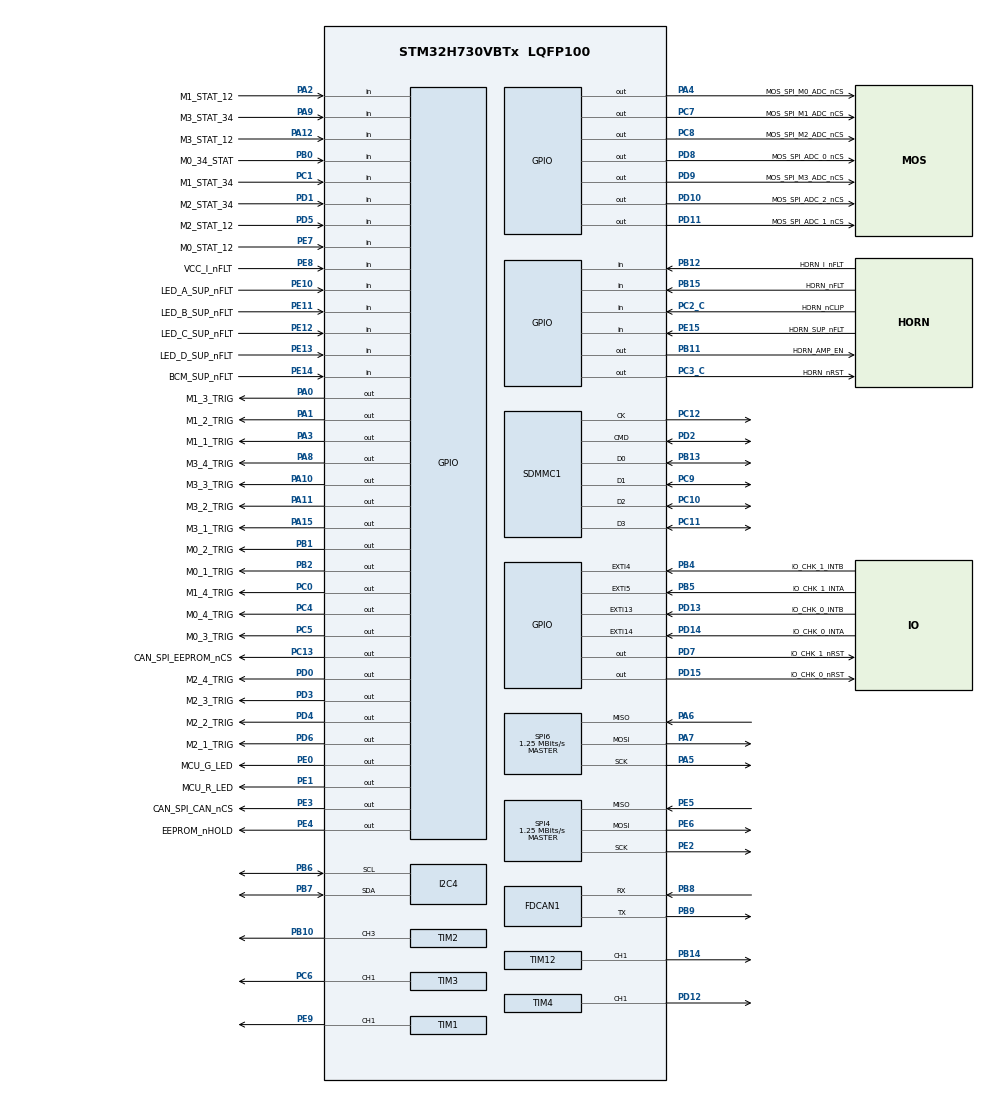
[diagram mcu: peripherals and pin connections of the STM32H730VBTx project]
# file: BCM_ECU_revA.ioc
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CORTEX_M7.default_mode_Activation=1
FDCAN1.CalculateBaudRateNominal=52083
FDCAN1.CalculateTimeBitNominal=19200
FDCAN1.CalculateTimeQuantumNominal=6400.0
I2C4.Timing=0x00000E14
Mcu.Family=STM32H7
Mcu.Name=STM32H730VBTx
Mcu.Package=LQFP100
NVIC.PriorityGroup=NVIC_PRIORITYGROUP_4
NVIC.TIM6_DAC_IRQn=true\:0\:0\:false\:false\:true\:true\:true\:true
PA0.GPIO_Label=M1_3_TRIG
PA0.Signal=GPIO_Output
PA1.GPIO_Label=M1_2_TRIG
PA1.Signal=GPIO_Output
PA10.GPIO_Label=M3_3_TRIG
PA10.Signal=GPIO_Output
PA11.GPIO_Label=M3_2_TRIG
PA11.Signal=GPIO_Output
PA12.GPIO_Label=M3_STAT_12
PA12.Signal=GPIO_Input
PA13(JTMS/SWDIO).Mode=Trace_Asynchronous_SW
PA13(JTMS/SWDIO).Signal=DEBUG_JTMS-SWDIO
PA14(JTCK/SWCLK).Mode=Trace_Asynchronous_SW
PA14(JTCK/SWCLK).Signal=DEBUG_JTCK-SWCLK
PA15(JTDI).GPIO_Label=M3_1_TRIG
PA15(JTDI).Signal=GPIO_Output
PA2.GPIO_Label=M1_STAT_12
PA2.Signal=GPIO_Input
PA3.GPIO_Label=M1_1_TRIG
PA3.Signal=GPIO_Output
PA4.GPIO_Label=MOS_SPI_M0_ADC_nCS
PA4.Signal=GPIO_Output
PA5.Mode=Full_Duplex_Master
PA5.Signal=SPI6_SCK
PA6.Mode=Full_Duplex_Master
PA6.Signal=SPI6_MISO
PA7.Mode=Full_Duplex_Master
PA7.Signal=SPI6_MOSI
PA8.GPIO_Label=M3_4_TRIG
PA8.Signal=GPIO_Output
PA9.GPIO_Label=M3_STAT_34
PA9.Signal=GPIO_Input
PB0.GPIO_Label=M0_34_STAT
PB0.Signal=GPIO_Input
PB1.GPIO_Label=M0_2_TRIG
PB1.Signal=GPIO_Output
PB10.Signal=S_TIM2_CH3
PB11.GPIO_Label=HORN_AMP_EN
PB11.Signal=GPIO_Output
PB12.GPIO_Label=HORN_I_nFLT
PB12.GPIO_PuPd=GPIO_PULLUP
PB12.Signal=GPIO_Input
PB13.Mode=SD_4_bits_Wide_bus
PB13.Signal=SDMMC1_D0
PB14.Signal=S_TIM12_CH1
PB15.GPIO_Label=HORN_nFLT
PB15.Signal=GPIO_Input
PB2.GPIO_Label=M0_1_TRIG
PB2.Signal=GPIO_Output
PB3(JTDO/TRACESWO).Mode=Trace_Asynchronous_SW
PB3(JTDO/TRACESWO).Signal=DEBUG_JTDO-SWO
PB4(NJTRST).GPIO_Label=IO_CHK_1_INTB
PB4(NJTRST).Signal=GPXTI4
PB5.GPIO_Label=IO_CHK_1_INTA
PB5.Signal=GPXTI5
PB6.Mode=I2C
PB6.Signal=I2C4_SCL
PB7.Mode=I2C
PB7.Signal=I2C4_SDA
PB8.Mode=FDCAN_Activate
PB8.Signal=FDCAN1_RX
PB9.Mode=FDCAN_Activate
PB9.Signal=FDCAN1_TX
PC0.GPIO_Label=M1_4_TRIG
PC0.Signal=GPIO_Output
PC1.GPIO_Label=M1_STAT_34
PC1.Signal=GPIO_Input
PC10.Mode=SD_4_bits_Wide_bus
PC10.Signal=SDMMC1_D2
PC11.Mode=SD_4_bits_Wide_bus
PC11.Signal=SDMMC1_D3
PC12.Mode=SD_4_bits_Wide_bus
PC12.Signal=SDMMC1_CK
PC13.GPIO_Label=CAN_SPI_EEPROM_nCS
PC13.Signal=GPIO_Output
PC14-OSC32_IN.Mode=LSE-External-Oscillator
PC14-OSC32_IN.Signal=RCC_OSC32_IN
PC15-OSC32_OUT.Mode=LSE-External-Oscillator
PC15-OSC32_OUT.Signal=RCC_OSC32_OUT
PC2_C.GPIO_Label=HORN_nCLIP
PC2_C.Signal=GPIO_Input
PC3_C.GPIO_Label=HORN_nRST
PC3_C.Signal=GPIO_Output
PC4.GPIO_Label=M0_4_TRIG
PC4.Signal=GPIO_Output
PC5.GPIO_Label=M0_3_TRIG
PC5.Signal=GPIO_Output
PC6.Signal=S_TIM3_CH1
PC7.GPIO_Label=MOS_SPI_M1_ADC_nCS
PC7.Signal=GPIO_Output
PC8.GPIO_Label=MOS_SPI_M2_ADC_nCS
PC8.Signal=GPIO_Output
PC9.Mode=SD_4_bits_Wide_bus
PC9.Signal=SDMMC1_D1
PD0.GPIO_Label=M2_4_TRIG
PD0.Signal=GPIO_Output
PD1.GPIO_Label=M2_STAT_34
PD1.Signal=GPIO_Input
PD10.GPIO_Label=MOS_SPI_ADC_2_nCS
PD10.Signal=GPIO_Output
PD11.GPIO_Label=MOS_SPI_ADC_1_nCS
PD11.Signal=GPIO_Output
PD12.Signal=S_TIM4_CH1
PD13.GPIO_Label=IO_CHK_0_INTB
PD13.Signal=GPXTI13
PD14.GPIO_Label=IO_CHK_0_INTA
PD14.Signal=GPXTI14
PD15.GPIO_Label=IO_CHK_0_nRST
PD15.Signal=GPIO_Output
PD2.Mode=SD_4_bits_Wide_bus
PD2.Signal=SDMMC1_CMD
PD3.GPIO_Label=M2_3_TRIG
PD3.Signal=GPIO_Output
PD4.GPIO_Label=M2_2_TRIG
PD4.Signal=GPIO_Output
PD5.GPIO_Label=M2_STAT_12
PD5.Signal=GPIO_Input
PD6.GPIO_Label=M2_1_TRIG
PD6.Signal=GPIO_Output
PD7.GPIO_Label=IO_CHK_1_nRST
PD7.Signal=GPIO_Output
PD8.GPIO_Label=MOS_SPI_ADC_0_nCS
PD8.Signal=GPIO_Output
PD9.GPIO_Label=MOS_SPI_M3_ADC_nCS
PD9.Signal=GPIO_Output
PE0.GPIO_Label=MCU_G_LED
PE0.Signal=GPIO_Output
PE1.GPIO_Label=MCU_R_LED
PE1.Signal=GPIO_Output
PE10.GPIO_Label=LED_A_SUP_nFLT
PE10.Signal=GPIO_Input
PE11.GPIO_Label=LED_B_SUP_nFLT
PE11.Signal=GPIO_Input
PE12.GPIO_Label=LED_C_SUP_nFLT
PE12.Signal=GPIO_Input
PE13.GPIO_Label=LED_D_SUP_nFLT
PE13.Signal=GPIO_Input
PE14.GPIO_Label=BCM_SUP_nFLT
PE14.Signal=GPIO_Input
PE15.GPIO_Label=HORN_SUP_nFLT
PE15.Signal=GPIO_Input
PE2.Mode=Full_Duplex_Master
PE2.Signal=SPI4_SCK
PE3.GPIO_Label=CAN_SPI_CAN_nCS
PE3.Signal=GPIO_Output
PE4.GPIO_Label=EEPROM_nHOLD
PE4.Signal=GPIO_Output
PE5.Mode=Full_Duplex_Master
PE5.Signal=SPI4_MISO
PE6.Mode=Full_Duplex_Master
PE6.Signal=SPI4_MOSI
PE7.GPIO_Label=M0_STAT_12
PE7.Signal=GPIO_Input
PE8.GPIO_Label=VCC_I_nFLT
PE8.Signal=GPIO_Input
PE9.Signal=S_TIM1_CH1
PH0-OSC_IN.Mode=HSE-External-Oscillator
PH0-OSC_IN.Signal=RCC_OSC_IN
PH1-OSC_OUT.Mode=HSE-External-Oscillator
PH1-OSC_OUT.Signal=RCC_OSC_OUT
ProjectManager.HeapSize=0x200
ProjectManager.StackSize=0x400
ProjectManager.TargetToolchain=STM32CubeIDE
RCC.ADCFreq_Value=120000000
RCC.APB1Freq_Value=15000000
RCC.APB2Freq_Value=15000000
RCC.APB3Freq_Value=15000000
RCC.APB4Freq_Value=15000000
RCC.CortexFreq_Value=120000000
RCC.DIVM1=5
RCC.DIVM2=5
RCC.DIVN1=48
RCC.DIVN2=48
RCC.DIVQ1=3
RCC.DIVQ2=96
RCC.FDCANCLockSelection=RCC_FDCANCLKSOURCE_PLL2
RCC.HCLKFreq_Value=15000000
RCC.HPRE=RCC_HCLK_DIV8
RCC.I2C4CLockSelection=RCC_I2C4CLKSOURCE_CSI
RCC.PLLSourceVirtual=RCC_PLLSOURCE_HSE
RCC.SPI6CLockSelection=RCC_SPI6CLKSOURCE_PLL2
RCC.SYSCLKFreq_VALUE=120000000
RCC.SYSCLKSource=RCC_SYSCLKSOURCE_PLLCLK
RCC.Spi45ClockSelection=RCC_SPI45CLKSOURCE_PLL2
RCC.USBFreq_Value=80000000
SH.S_TIM12_CH1.0=TIM12_CH1,PWM Generation1 CH1
SH.S_TIM1_CH1.0=TIM1_CH1,PWM Generation1 CH1
SH.S_TIM2_CH3.0=TIM2_CH3,PWM Generation3 CH3
SH.S_TIM3_CH1.0=TIM3_CH1,PWM Generation1 CH1
SH.S_TIM4_CH1.0=TIM4_CH1,PWM Generation1 CH1
SPI4.CalculateBaudRate=1.25 MBits/s
SPI4.Direction=SPI_DIRECTION_2LINES
SPI4.Mode=SPI_MODE_MASTER
SPI4.VirtualType=VM_MASTER
SPI6.BaudRatePrescaler=SPI_BAUDRATEPRESCALER_2
SPI6.CalculateBaudRate=1.25 MBits/s
SPI6.Direction=SPI_DIRECTION_2LINES
SPI6.Mode=SPI_MODE_MASTER
SPI6.VirtualType=VM_MASTER
TIM1.Channel-PWM\ Generation1\ CH1=TIM_CHANNEL_1
TIM12.Channel-PWM\ Generation1\ CH1=TIM_CHANNEL_1
TIM2.Channel-PWM\ Generation3\ CH3=TIM_CHANNEL_3
TIM3.Channel-PWM\ Generation1\ CH1=TIM_CHANNEL_1
TIM4.Channel-PWM\ Generation1\ CH1=TIM_CHANNEL_1
TIM6.AutoReloadPreload=TIM_AUTORELOAD_PRELOAD_ENABLE
TIM6.Period=99
TIM6.Prescaler=1499
VP_MEMORYMAP_VS_MEMORYMAP.Mode=CurAppReg
VP_TIM6_VS_ClockSourceINT.Mode=Enable_Timer
board=custom

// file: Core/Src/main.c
/* USER CODE BEGIN Header */
/**
  ******************************************************************************
  * @file           : main.c
  * @brief          : Main program body
  ******************************************************************************
  * @attention
  *
  * Copyright (c) 2025 STMicroelectronics.
  * All rights reserved.
  *
  * This software is licensed under terms that can be found in the LICENSE file
  * in the root directory of this software component.
  * If no LICENSE file comes with this software, it is provided AS-IS.
  *
  ******************************************************************************
  */
/* USER CODE END Header */
#include "main.h"

/* USER CODE BEGIN Includes */

#include "ADC108S022.h"
#include "MCP23017.h"
#include "tcan1146.h"
#include "ws2812b.h"

#include "state_manager.h"
#include "light_manager.h"

/* USER CODE END Includes */

FDCAN_HandleTypeDef hfdcan1;

I2C_HandleTypeDef hi2c4;

SD_HandleTypeDef hsd1;

SPI_HandleTypeDef hspi4;
SPI_HandleTypeDef hspi6;

TIM_HandleTypeDef htim1;
TIM_HandleTypeDef htim2;
TIM_HandleTypeDef htim3;
TIM_HandleTypeDef htim4;
TIM_HandleTypeDef htim6;
TIM_HandleTypeDef htim12;

/* USER CODE BEGIN PV */

ADC108S022 ADC_MOS_0 = {
    .hspi = &hspi6,
    .cs_port = GPIOA,        // CS on PA4
    .cs_pin = GPIO_PIN_4
};

ADC108S022 ADC_MOS_1 = {
    .hspi = &hspi6,
    .cs_port = GPIOC,        // CS on PC7
    .cs_pin = GPIO_PIN_7
};

ADC108S022 ADC_MOS_2 = {
    .hspi = &hspi6,
    .cs_port = GPIOC,        // CS on PC8
    .cs_pin = GPIO_PIN_8
};

ADC108S022 ADC_MOS_3 = {
    .hspi = &hspi6,
    .cs_port = GPIOD,        // CS on PD9
    .cs_pin = GPIO_PIN_9
};

ADC108S022 ADC_GEN_0 = {
    .hspi = &hspi6,
    .cs_port = GPIOD,        // CS on PD8
    .cs_pin = GPIO_PIN_8
};

ADC108S022 ADC_GEN_1 = {
    .hspi = &hspi6,
    .cs_port = GPIOD,        // CS on PD11
    .cs_pin = GPIO_PIN_11
};

ADC108S022 ADC_GEN_2 = {
    .hspi = &hspi6,
    .cs_port = GPIOD,        // CS on PD10
    .cs_pin = GPIO_PIN_10
};

MCP23017 MCP23017_0 = {			//TODO: update and make interrupt code
    .i2c = &hi2c4,             // I2C1 peripheral
    .i2c_addr = 0x20,          // A2/A1/A0 = GND
    .rst_port = GPIOD,         // RST on PD15
    .rst_pin = GPIO_PIN_15,
    .inta_port = GPIOD,        // INTA on PD14
    .inta_pin = GPIO_PIN_14,
    .intb_port = GPIOD,        // INTB on PD13
    .intb_pin = GPIO_PIN_13
};

MCP23017 MCP23017_1 = { 		//TODO: update
    .i2c = &hi2c4,             // I2C1 peripheral
    .i2c_addr = 0x20,          // A2/A1/A0 = GND
    .rst_port = GPIOD,         // RST on PD7
    .rst_pin = GPIO_PIN_7,
    .inta_port = GPIOB,        // INTA on PB5
    .inta_pin = GPIO_PIN_5,
    .intb_port = GPIOB,        // INTB on PB4
    .intb_pin = GPIO_PIN_4
};

TCAN1146 tcan = {
    .hspi = &hspi4,          // SPI1
    .cs_port = GPIOE,        // CS on PE3
    .cs_pin = GPIO_PIN_3
};

WS2812B_Strip strip1 = {
    .htim = &htim1,               // TIM1
    .channel = TIM_CHANNEL_1,     // PWM Channel 1
    .hdma = &hdma_tim1_ch1,       // DMA for TIM1_CH1
    .num_leds = 30,               // 30 LEDs in this strip
    .pwm_buffer = {0}             // Zero-init buffer
};

WS2812B_Strip strip2 = {
    .htim = &htim2,               // TIM2
    .channel = TIM_CHANNEL_2,     // PWM Channel 2
    .hdma = &hdma_tim2_ch2,       // DMA for TIM2_CH2
    .num_leds = 60,               // 60 LEDs in this strip
    .pwm_buffer = {0}             // Zero-init buffer
};

uint32_t wake_id = 0x12345678;	//TODO: UPDATE THESE VARS
uint8_t wake_payload[] = {0xAA, 0xBB};
uint8_t wake_payload_length = 2;

/* USER CODE END PV */

void SystemClock_Config(void);
void PeriphCommonClock_Config(void);
static void MPU_Config(void);
static void MX_GPIO_Init(void);
static void MX_FDCAN1_Init(void);
static void MX_I2C4_Init(void);
static void MX_SDMMC1_SD_Init(void);
static void MX_SPI4_Init(void);
static void MX_SPI6_Init(void);
static void MX_TIM1_Init(void);
static void MX_TIM2_Init(void);
static void MX_TIM3_Init(void);
static void MX_TIM4_Init(void);
static void MX_TIM12_Init(void);
static void MX_TIM6_Init(void);

int main(void)
{

  /* MPU Configuration--------------------------------------------------------*/
  MPU_Config();

  /* MCU Configuration--------------------------------------------------------*/

  /* Reset of all peripherals, Initializes the Flash interface and the Systick. */
  HAL_Init();

  /* Configure the system clock */
  SystemClock_Config();

  /* Configure the peripherals common clocks */
  PeriphCommonClock_Config();

  /* Initialize all configured peripherals */
  MX_GPIO_Init();
  MX_FDCAN1_Init();
  MX_I2C4_Init();
  MX_SDMMC1_SD_Init();
  MX_SPI4_Init();
  MX_SPI6_Init();
  MX_TIM1_Init();
  MX_TIM2_Init();
  MX_TIM3_Init();
  MX_TIM4_Init();
  MX_TIM12_Init();
  MX_TIM6_Init();
  /* USER CODE BEGIN 2 */

  ADC108S022_Init(&ADC_MOS_0);
  ADC108S022_Init(&ADC_MOS_1);
  ADC108S022_Init(&ADC_MOS_2);
  ADC108S022_Init(&ADC_MOS_3);
  ADC108S022_Init(&ADC_GEN_0);
  ADC108S022_Init(&ADC_GEN_1);
  ADC108S022_Init(&ADC_GEN_2);

  MCP23017_Init(&MCP23017_0);
  MCP23017_Init(&MCP23017_1);

  TCAN1146_Init(&tcan, wake_id, wake_payload, wake_payload_length);

  // Initialize strips (assigns hardware, uses num_leds)
  WS2812B_Init(&strip1);
  WS2812B_Init(&strip2);

  //TIM6 is used for regular lighting update interrupts
  HAL_TIM_Base_Start_IT(&htim6);  // Start TIM6 interrupts

  /* USER CODE END 2 */

  /* Infinite loop */
  while (1)
  {

  }
}

// Callback for interrupts caused by timers
void HAL_TIM_PeriodElapsedCallback(TIM_HandleTypeDef *htim) {
    if (htim == &htim6) {
        //update lights
    }
}

void SystemClock_Config(void)
{
  RCC_OscInitTypeDef RCC_OscInitStruct = {0};
  RCC_ClkInitTypeDef RCC_ClkInitStruct = {0};

  /** Supply configuration update enable
  */
  HAL_PWREx_ConfigSupply(PWR_LDO_SUPPLY);

  /** Configure the main internal regulator output voltage
  */
  __HAL_PWR_VOLTAGESCALING_CONFIG(PWR_REGULATOR_VOLTAGE_SCALE3);

  while(!__HAL_PWR_GET_FLAG(PWR_FLAG_VOSRDY)) {}

  /** Initializes the RCC Oscillators according to the specified parameters
  * in the RCC_OscInitTypeDef structure.
  */
  RCC_OscInitStruct.OscillatorType = RCC_OSCILLATORTYPE_CSI|RCC_OSCILLATORTYPE_HSE;
  RCC_OscInitStruct.HSEState = RCC_HSE_ON;
  RCC_OscInitStruct.CSIState = RCC_CSI_ON;
  RCC_OscInitStruct.CSICalibrationValue = 16;
  RCC_OscInitStruct.PLL.PLLState = RCC_PLL_ON;
  RCC_OscInitStruct.PLL.PLLSource = RCC_PLLSOURCE_HSE;
  RCC_OscInitStruct.PLL.PLLM = 5;
  RCC_OscInitStruct.PLL.PLLN = 48;
  RCC_OscInitStruct.PLL.PLLP = 2;
  RCC_OscInitStruct.PLL.PLLQ = 3;
  RCC_OscInitStruct.PLL.PLLR = 2;
  RCC_OscInitStruct.PLL.PLLRGE = RCC_PLL1VCIRANGE_2;
  RCC_OscInitStruct.PLL.PLLVCOSEL = RCC_PLL1VCOWIDE;
  RCC_OscInitStruct.PLL.PLLFRACN = 0;
  if (HAL_RCC_OscConfig(&RCC_OscInitStruct) != HAL_OK)
  {
    Error_Handler();
  }

  /** Initializes the CPU, AHB and APB buses clocks
  */
  RCC_ClkInitStruct.ClockType = RCC_CLOCKTYPE_HCLK|RCC_CLOCKTYPE_SYSCLK
                              |RCC_CLOCKTYPE_PCLK1|RCC_CLOCKTYPE_PCLK2
                              |RCC_CLOCKTYPE_D3PCLK1|RCC_CLOCKTYPE_D1PCLK1;
  RCC_ClkInitStruct.SYSCLKSource = RCC_SYSCLKSOURCE_PLLCLK;
  RCC_ClkInitStruct.SYSCLKDivider = RCC_SYSCLK_DIV1;
  RCC_ClkInitStruct.AHBCLKDivider = RCC_HCLK_DIV8;
  RCC_ClkInitStruct.APB3CLKDivider = RCC_APB3_DIV1;
  RCC_ClkInitStruct.APB1CLKDivider = RCC_APB1_DIV1;
  RCC_ClkInitStruct.APB2CLKDivider = RCC_APB2_DIV1;
  RCC_ClkInitStruct.APB4CLKDivider = RCC_APB4_DIV1;

  if (HAL_RCC_ClockConfig(&RCC_ClkInitStruct, FLASH_LATENCY_0) != HAL_OK)
  {
    Error_Handler();
  }
}

void PeriphCommonClock_Config(void)
{
  RCC_PeriphCLKInitTypeDef PeriphClkInitStruct = {0};

  /** Initializes the peripherals clock
  */
  PeriphClkInitStruct.PeriphClockSelection = RCC_PERIPHCLK_SPI6|RCC_PERIPHCLK_SPI4
                              |RCC_PERIPHCLK_FDCAN;
  PeriphClkInitStruct.PLL2.PLL2M = 5;
  PeriphClkInitStruct.PLL2.PLL2N = 48;
  PeriphClkInitStruct.PLL2.PLL2P = 2;
  PeriphClkInitStruct.PLL2.PLL2Q = 96;
  PeriphClkInitStruct.PLL2.PLL2R = 2;
  PeriphClkInitStruct.PLL2.PLL2RGE = RCC_PLL2VCIRANGE_2;
  PeriphClkInitStruct.PLL2.PLL2VCOSEL = RCC_PLL2VCOWIDE;
  PeriphClkInitStruct.PLL2.PLL2FRACN = 0;
  PeriphClkInitStruct.Spi45ClockSelection = RCC_SPI45CLKSOURCE_PLL2;
  PeriphClkInitStruct.FdcanClockSelection = RCC_FDCANCLKSOURCE_PLL2;
  PeriphClkInitStruct.Spi6ClockSelection = RCC_SPI6CLKSOURCE_PLL2;
  if (HAL_RCCEx_PeriphCLKConfig(&PeriphClkInitStruct) != HAL_OK)
  {
    Error_Handler();
  }
}

static void MX_FDCAN1_Init(void)
{

  hfdcan1.Instance = FDCAN1;
  hfdcan1.Init.FrameFormat = FDCAN_FRAME_CLASSIC;
  hfdcan1.Init.Mode = FDCAN_MODE_NORMAL;
  hfdcan1.Init.AutoRetransmission = DISABLE;
  hfdcan1.Init.TransmitPause = DISABLE;
  hfdcan1.Init.ProtocolException = DISABLE;
  hfdcan1.Init.NominalPrescaler = 16;
  hfdcan1.Init.NominalSyncJumpWidth = 1;
  hfdcan1.Init.NominalTimeSeg1 = 1;
  hfdcan1.Init.NominalTimeSeg2 = 1;
  hfdcan1.Init.DataPrescaler = 1;
  hfdcan1.Init.DataSyncJumpWidth = 1;
  hfdcan1.Init.DataTimeSeg1 = 1;
  hfdcan1.Init.DataTimeSeg2 = 1;
  hfdcan1.Init.MessageRAMOffset = 0;
  hfdcan1.Init.StdFiltersNbr = 0;
  hfdcan1.Init.ExtFiltersNbr = 0;
  hfdcan1.Init.RxFifo0ElmtsNbr = 0;
  hfdcan1.Init.RxFifo0ElmtSize = FDCAN_DATA_BYTES_8;
  hfdcan1.Init.RxFifo1ElmtsNbr = 0;
  hfdcan1.Init.RxFifo1ElmtSize = FDCAN_DATA_BYTES_8;
  hfdcan1.Init.RxBuffersNbr = 0;
  hfdcan1.Init.RxBufferSize = FDCAN_DATA_BYTES_8;
  hfdcan1.Init.TxEventsNbr = 0;
  hfdcan1.Init.TxBuffersNbr = 0;
  hfdcan1.Init.TxFifoQueueElmtsNbr = 0;
  hfdcan1.Init.TxFifoQueueMode = FDCAN_TX_FIFO_OPERATION;
  hfdcan1.Init.TxElmtSize = FDCAN_DATA_BYTES_8;
  if (HAL_FDCAN_Init(&hfdcan1) != HAL_OK)
  {
    Error_Handler();
  }

}

static void MX_I2C4_Init(void)
{

  hi2c4.Instance = I2C4;
  hi2c4.Init.Timing = 0x00000E14;
  hi2c4.Init.OwnAddress1 = 0;
  hi2c4.Init.AddressingMode = I2C_ADDRESSINGMODE_7BIT;
  hi2c4.Init.DualAddressMode = I2C_DUALADDRESS_DISABLE;
  hi2c4.Init.OwnAddress2 = 0;
  hi2c4.Init.OwnAddress2Masks = I2C_OA2_NOMASK;
  hi2c4.Init.GeneralCallMode = I2C_GENERALCALL_DISABLE;
  hi2c4.Init.NoStretchMode = I2C_NOSTRETCH_DISABLE;
  if (HAL_I2C_Init(&hi2c4) != HAL_OK)
  {
    Error_Handler();
  }

  /** Configure Analogue filter
  */
  if (HAL_I2CEx_ConfigAnalogFilter(&hi2c4, I2C_ANALOGFILTER_ENABLE) != HAL_OK)
  {
    Error_Handler();
  }

  /** Configure Digital filter
  */
  if (HAL_I2CEx_ConfigDigitalFilter(&hi2c4, 0) != HAL_OK)
  {
    Error_Handler();
  }

}

static void MX_SDMMC1_SD_Init(void)
{

  hsd1.Instance = SDMMC1;
  hsd1.Init.ClockEdge = SDMMC_CLOCK_EDGE_RISING;
  hsd1.Init.ClockPowerSave = SDMMC_CLOCK_POWER_SAVE_DISABLE;
  hsd1.Init.BusWide = SDMMC_BUS_WIDE_4B;
  hsd1.Init.HardwareFlowControl = SDMMC_HARDWARE_FLOW_CONTROL_DISABLE;
  hsd1.Init.ClockDiv = 0;
  if (HAL_SD_Init(&hsd1) != HAL_OK)
  {
    Error_Handler();
  }

}

static void MX_SPI4_Init(void)
{

  /* SPI4 parameter configuration*/
  hspi4.Instance = SPI4;
  hspi4.Init.Mode = SPI_MODE_MASTER;
  hspi4.Init.Direction = SPI_DIRECTION_2LINES;
  hspi4.Init.DataSize = SPI_DATASIZE_4BIT;
  hspi4.Init.CLKPolarity = SPI_POLARITY_LOW;
  hspi4.Init.CLKPhase = SPI_PHASE_1EDGE;
  hspi4.Init.NSS = SPI_NSS_SOFT;
  hspi4.Init.BaudRatePrescaler = SPI_BAUDRATEPRESCALER_2;
  hspi4.Init.FirstBit = SPI_FIRSTBIT_MSB;
  hspi4.Init.TIMode = SPI_TIMODE_DISABLE;
  hspi4.Init.CRCCalculation = SPI_CRCCALCULATION_DISABLE;
  hspi4.Init.CRCPolynomial = 0x0;
  hspi4.Init.NSSPMode = SPI_NSS_PULSE_ENABLE;
  hspi4.Init.NSSPolarity = SPI_NSS_POLARITY_LOW;
  hspi4.Init.FifoThreshold = SPI_FIFO_THRESHOLD_01DATA;
  hspi4.Init.TxCRCInitializationPattern = SPI_CRC_INITIALIZATION_ALL_ZERO_PATTERN;
  hspi4.Init.RxCRCInitializationPattern = SPI_CRC_INITIALIZATION_ALL_ZERO_PATTERN;
  hspi4.Init.MasterSSIdleness = SPI_MASTER_SS_IDLENESS_00CYCLE;
  hspi4.Init.MasterInterDataIdleness = SPI_MASTER_INTERDATA_IDLENESS_00CYCLE;
  hspi4.Init.MasterReceiverAutoSusp = SPI_MASTER_RX_AUTOSUSP_DISABLE;
  hspi4.Init.MasterKeepIOState = SPI_MASTER_KEEP_IO_STATE_DISABLE;
  hspi4.Init.IOSwap = SPI_IO_SWAP_DISABLE;
  if (HAL_SPI_Init(&hspi4) != HAL_OK)
  {
    Error_Handler();
  }

}

static void MX_SPI6_Init(void)
{

  /* SPI6 parameter configuration*/
  hspi6.Instance = SPI6;
  hspi6.Init.Mode = SPI_MODE_MASTER;
  hspi6.Init.Direction = SPI_DIRECTION_2LINES;
  hspi6.Init.DataSize = SPI_DATASIZE_4BIT;
  hspi6.Init.CLKPolarity = SPI_POLARITY_LOW;
  hspi6.Init.CLKPhase = SPI_PHASE_1EDGE;
  hspi6.Init.NSS = SPI_NSS_SOFT;
  hspi6.Init.BaudRatePrescaler = SPI_BAUDRATEPRESCALER_2;
  hspi6.Init.FirstBit = SPI_FIRSTBIT_MSB;
  hspi6.Init.TIMode = SPI_TIMODE_DISABLE;
  hspi6.Init.CRCCalculation = SPI_CRCCALCULATION_DISABLE;
  hspi6.Init.CRCPolynomial = 0x0;
  hspi6.Init.NSSPMode = SPI_NSS_PULSE_ENABLE;
  hspi6.Init.NSSPolarity = SPI_NSS_POLARITY_LOW;
  hspi6.Init.FifoThreshold = SPI_FIFO_THRESHOLD_01DATA;
  hspi6.Init.TxCRCInitializationPattern = SPI_CRC_INITIALIZATION_ALL_ZERO_PATTERN;
  hspi6.Init.RxCRCInitializationPattern = SPI_CRC_INITIALIZATION_ALL_ZERO_PATTERN;
  hspi6.Init.MasterSSIdleness = SPI_MASTER_SS_IDLENESS_00CYCLE;
  hspi6.Init.MasterInterDataIdleness = SPI_MASTER_INTERDATA_IDLENESS_00CYCLE;
  hspi6.Init.MasterReceiverAutoSusp = SPI_MASTER_RX_AUTOSUSP_DISABLE;
  hspi6.Init.MasterKeepIOState = SPI_MASTER_KEEP_IO_STATE_DISABLE;
  hspi6.Init.IOSwap = SPI_IO_SWAP_DISABLE;
  if (HAL_SPI_Init(&hspi6) != HAL_OK)
  {
    Error_Handler();
  }

}

static void MX_TIM1_Init(void)
{

  TIM_MasterConfigTypeDef sMasterConfig = {0};
  TIM_OC_InitTypeDef sConfigOC = {0};
  TIM_BreakDeadTimeConfigTypeDef sBreakDeadTimeConfig = {0};

  htim1.Instance = TIM1;
  htim1.Init.Prescaler = 0;
  htim1.Init.CounterMode = TIM_COUNTERMODE_UP;
  htim1.Init.Period = 65535;
  htim1.Init.ClockDivision = TIM_CLOCKDIVISION_DIV1;
  htim1.Init.RepetitionCounter = 0;
  htim1.Init.AutoReloadPreload = TIM_AUTORELOAD_PRELOAD_DISABLE;
  if (HAL_TIM_PWM_Init(&htim1) != HAL_OK)
  {
    Error_Handler();
  }
  sMasterConfig.MasterOutputTrigger = TIM_TRGO_RESET;
  sMasterConfig.MasterOutputTrigger2 = TIM_TRGO2_RESET;
  sMasterConfig.MasterSlaveMode = TIM_MASTERSLAVEMODE_DISABLE;
  if (HAL_TIMEx_MasterConfigSynchronization(&htim1, &sMasterConfig) != HAL_OK)
  {
    Error_Handler();
  }
  sConfigOC.OCMode = TIM_OCMODE_PWM1;
  sConfigOC.Pulse = 0;
  sConfigOC.OCPolarity = TIM_OCPOLARITY_HIGH;
  sConfigOC.OCNPolarity = TIM_OCNPOLARITY_HIGH;
  sConfigOC.OCFastMode = TIM_OCFAST_DISABLE;
  sConfigOC.OCIdleState = TIM_OCIDLESTATE_RESET;
  sConfigOC.OCNIdleState = TIM_OCNIDLESTATE_RESET;
  if (HAL_TIM_PWM_ConfigChannel(&htim1, &sConfigOC, TIM_CHANNEL_1) != HAL_OK)
  {
    Error_Handler();
  }
  sBreakDeadTimeConfig.OffStateRunMode = TIM_OSSR_DISABLE;
  sBreakDeadTimeConfig.OffStateIDLEMode = TIM_OSSI_DISABLE;
  sBreakDeadTimeConfig.LockLevel = TIM_LOCKLEVEL_OFF;
  sBreakDeadTimeConfig.DeadTime = 0;
  sBreakDeadTimeConfig.BreakState = TIM_BREAK_DISABLE;
  sBreakDeadTimeConfig.BreakPolarity = TIM_BREAKPOLARITY_HIGH;
  sBreakDeadTimeConfig.BreakFilter = 0;
  sBreakDeadTimeConfig.Break2State = TIM_BREAK2_DISABLE;
  sBreakDeadTimeConfig.Break2Polarity = TIM_BREAK2POLARITY_HIGH;
  sBreakDeadTimeConfig.Break2Filter = 0;
  sBreakDeadTimeConfig.AutomaticOutput = TIM_AUTOMATICOUTPUT_DISABLE;
  if (HAL_TIMEx_ConfigBreakDeadTime(&htim1, &sBreakDeadTimeConfig) != HAL_OK)
  {
    Error_Handler();
  }
  HAL_TIM_MspPostInit(&htim1);

}

static void MX_TIM2_Init(void)
{

  TIM_MasterConfigTypeDef sMasterConfig = {0};
  TIM_OC_InitTypeDef sConfigOC = {0};

  htim2.Instance = TIM2;
  htim2.Init.Prescaler = 0;
  htim2.Init.CounterMode = TIM_COUNTERMODE_UP;
  htim2.Init.Period = 4294967295;
  htim2.Init.ClockDivision = TIM_CLOCKDIVISION_DIV1;
  htim2.Init.AutoReloadPreload = TIM_AUTORELOAD_PRELOAD_DISABLE;
  if (HAL_TIM_PWM_Init(&htim2) != HAL_OK)
  {
    Error_Handler();
  }
  sMasterConfig.MasterOutputTrigger = TIM_TRGO_RESET;
  sMasterConfig.MasterSlaveMode = TIM_MASTERSLAVEMODE_DISABLE;
  if (HAL_TIMEx_MasterConfigSynchronization(&htim2, &sMasterConfig) != HAL_OK)
  {
    Error_Handler();
  }
  sConfigOC.OCMode = TIM_OCMODE_PWM1;
  sConfigOC.Pulse = 0;
  sConfigOC.OCPolarity = TIM_OCPOLARITY_HIGH;
  sConfigOC.OCFastMode = TIM_OCFAST_DISABLE;
  if (HAL_TIM_PWM_ConfigChannel(&htim2, &sConfigOC, TIM_CHANNEL_3) != HAL_OK)
  {
    Error_Handler();
  }
  HAL_TIM_MspPostInit(&htim2);

}

static void MX_TIM3_Init(void)
{

  TIM_MasterConfigTypeDef sMasterConfig = {0};
  TIM_OC_InitTypeDef sConfigOC = {0};

  htim3.Instance = TIM3;
  htim3.Init.Prescaler = 0;
  htim3.Init.CounterMode = TIM_COUNTERMODE_UP;
  htim3.Init.Period = 65535;
  htim3.Init.ClockDivision = TIM_CLOCKDIVISION_DIV1;
  htim3.Init.AutoReloadPreload = TIM_AUTORELOAD_PRELOAD_DISABLE;
  if (HAL_TIM_PWM_Init(&htim3) != HAL_OK)
  {
    Error_Handler();
  }
  sMasterConfig.MasterOutputTrigger = TIM_TRGO_RESET;
  sMasterConfig.MasterSlaveMode = TIM_MASTERSLAVEMODE_DISABLE;
  if (HAL_TIMEx_MasterConfigSynchronization(&htim3, &sMasterConfig) != HAL_OK)
  {
    Error_Handler();
  }
  sConfigOC.OCMode = TIM_OCMODE_PWM1;
  sConfigOC.Pulse = 0;
  sConfigOC.OCPolarity = TIM_OCPOLARITY_HIGH;
  sConfigOC.OCFastMode = TIM_OCFAST_DISABLE;
  if (HAL_TIM_PWM_ConfigChannel(&htim3, &sConfigOC, TIM_CHANNEL_1) != HAL_OK)
  {
    Error_Handler();
  }
  HAL_TIM_MspPostInit(&htim3);

}

static void MX_TIM4_Init(void)
{

  TIM_MasterConfigTypeDef sMasterConfig = {0};
  TIM_OC_InitTypeDef sConfigOC = {0};

  htim4.Instance = TIM4;
  htim4.Init.Prescaler = 0;
  htim4.Init.CounterMode = TIM_COUNTERMODE_UP;
  htim4.Init.Period = 65535;
  htim4.Init.ClockDivision = TIM_CLOCKDIVISION_DIV1;
  htim4.Init.AutoReloadPreload = TIM_AUTORELOAD_PRELOAD_DISABLE;
  if (HAL_TIM_PWM_Init(&htim4) != HAL_OK)
  {
    Error_Handler();
  }
  sMasterConfig.MasterOutputTrigger = TIM_TRGO_RESET;
  sMasterConfig.MasterSlaveMode = TIM_MASTERSLAVEMODE_DISABLE;
  if (HAL_TIMEx_MasterConfigSynchronization(&htim4, &sMasterConfig) != HAL_OK)
  {
    Error_Handler();
  }
  sConfigOC.OCMode = TIM_OCMODE_PWM1;
  sConfigOC.Pulse = 0;
  sConfigOC.OCPolarity = TIM_OCPOLARITY_HIGH;
  sConfigOC.OCFastMode = TIM_OCFAST_DISABLE;
  if (HAL_TIM_PWM_ConfigChannel(&htim4, &sConfigOC, TIM_CHANNEL_1) != HAL_OK)
  {
    Error_Handler();
  }
  HAL_TIM_MspPostInit(&htim4);

}

static void MX_TIM6_Init(void)
{

  TIM_MasterConfigTypeDef sMasterConfig = {0};

  htim6.Instance = TIM6;
  htim6.Init.Prescaler = 1499;
  htim6.Init.CounterMode = TIM_COUNTERMODE_UP;
  htim6.Init.Period = 99;
  htim6.Init.AutoReloadPreload = TIM_AUTORELOAD_PRELOAD_ENABLE;
  if (HAL_TIM_Base_Init(&htim6) != HAL_OK)
  {
    Error_Handler();
  }
  sMasterConfig.MasterOutputTrigger = TIM_TRGO_RESET;
  sMasterConfig.MasterSlaveMode = TIM_MASTERSLAVEMODE_DISABLE;
  if (HAL_TIMEx_MasterConfigSynchronization(&htim6, &sMasterConfig) != HAL_OK)
  {
    Error_Handler();
  }

}

static void MX_TIM12_Init(void)
{

  TIM_MasterConfigTypeDef sMasterConfig = {0};
  TIM_OC_InitTypeDef sConfigOC = {0};

  htim12.Instance = TIM12;
  htim12.Init.Prescaler = 0;
  htim12.Init.CounterMode = TIM_COUNTERMODE_UP;
  htim12.Init.Period = 65535;
  htim12.Init.ClockDivision = TIM_CLOCKDIVISION_DIV1;
  htim12.Init.AutoReloadPreload = TIM_AUTORELOAD_PRELOAD_DISABLE;
  if (HAL_TIM_PWM_Init(&htim12) != HAL_OK)
  {
    Error_Handler();
  }
  sMasterConfig.MasterOutputTrigger = TIM_TRGO_RESET;
  sMasterConfig.MasterSlaveMode = TIM_MASTERSLAVEMODE_DISABLE;
  if (HAL_TIMEx_MasterConfigSynchronization(&htim12, &sMasterConfig) != HAL_OK)
  {
    Error_Handler();
  }
  sConfigOC.OCMode = TIM_OCMODE_PWM1;
  sConfigOC.Pulse = 0;
  sConfigOC.OCPolarity = TIM_OCPOLARITY_HIGH;
  sConfigOC.OCFastMode = TIM_OCFAST_DISABLE;
  if (HAL_TIM_PWM_ConfigChannel(&htim12, &sConfigOC, TIM_CHANNEL_1) != HAL_OK)
  {
    Error_Handler();
  }
  HAL_TIM_MspPostInit(&htim12);

}

static void MX_GPIO_Init(void)
{
  GPIO_InitTypeDef GPIO_InitStruct = {0};

  /* GPIO Ports Clock Enable */
  __HAL_RCC_GPIOE_CLK_ENABLE();
  __HAL_RCC_GPIOC_CLK_ENABLE();
  __HAL_RCC_GPIOH_CLK_ENABLE();
  __HAL_RCC_GPIOA_CLK_ENABLE();
  __HAL_RCC_GPIOB_CLK_ENABLE();
  __HAL_RCC_GPIOD_CLK_ENABLE();

  /*Configure GPIO pin Output Level */
  HAL_GPIO_WritePin(GPIOE, CAN_SPI_CAN_nCS_Pin|EEPROM_nHOLD_Pin|MCU_G_LED_Pin|MCU_R_LED_Pin, GPIO_PIN_RESET);

  /*Configure GPIO pin Output Level */
  HAL_GPIO_WritePin(GPIOC, CAN_SPI_EEPROM_nCS_Pin|M1_4_TRIG_Pin|HORN_nRST_Pin|M0_4_TRIG_Pin
                          |M0_3_TRIG_Pin|MOS_SPI_M1_ADC_nCS_Pin|MOS_SPI_M2_ADC_nCS_Pin, GPIO_PIN_RESET);

  /*Configure GPIO pin Output Level */
  HAL_GPIO_WritePin(GPIOA, M1_3_TRIG_Pin|M1_2_TRIG_Pin|M1_1_TRIG_Pin|MOS_SPI_M0_ADC_nCS_Pin
                          |M3_4_TRIG_Pin|M3_3_TRIG_Pin|M3_2_TRIG_Pin|M3_1_TRIG_Pin, GPIO_PIN_RESET);

  /*Configure GPIO pin Output Level */
  HAL_GPIO_WritePin(GPIOB, M0_2_TRIG_Pin|M0_1_TRIG_Pin|HORN_AMP_EN_Pin, GPIO_PIN_RESET);

  /*Configure GPIO pin Output Level */
  HAL_GPIO_WritePin(GPIOD, MOS_SPI_ADC_0_nCS_Pin|MOS_SPI_M3_ADC_nCS_Pin|MOS_SPI_ADC_2_nCS_Pin|MOS_SPI_ADC_1_nCS_Pin
                          |IO_CHK_0_nRST_Pin|M2_4_TRIG_Pin|M2_3_TRIG_Pin|M2_2_TRIG_Pin
                          |M2_1_TRIG_Pin|IO_CHK_1_nRST_Pin, GPIO_PIN_RESET);

  /*Configure GPIO pins : CAN_SPI_CAN_nCS_Pin EEPROM_nHOLD_Pin MCU_G_LED_Pin MCU_R_LED_Pin */
  GPIO_InitStruct.Pin = CAN_SPI_CAN_nCS_Pin|EEPROM_nHOLD_Pin|MCU_G_LED_Pin|MCU_R_LED_Pin;
  GPIO_InitStruct.Mode = GPIO_MODE_OUTPUT_PP;
  GPIO_InitStruct.Pull = GPIO_NOPULL;
  GPIO_InitStruct.Speed = GPIO_SPEED_FREQ_LOW;
  HAL_GPIO_Init(GPIOE, &GPIO_InitStruct);

  /*Configure GPIO pins : CAN_SPI_EEPROM_nCS_Pin M1_4_TRIG_Pin HORN_nRST_Pin M0_4_TRIG_Pin
                           M0_3_TRIG_Pin MOS_SPI_M1_ADC_nCS_Pin MOS_SPI_M2_ADC_nCS_Pin */
  GPIO_InitStruct.Pin = CAN_SPI_EEPROM_nCS_Pin|M1_4_TRIG_Pin|HORN_nRST_Pin|M0_4_TRIG_Pin
                          |M0_3_TRIG_Pin|MOS_SPI_M1_ADC_nCS_Pin|MOS_SPI_M2_ADC_nCS_Pin;
  GPIO_InitStruct.Mode = GPIO_MODE_OUTPUT_PP;
  GPIO_InitStruct.Pull = GPIO_NOPULL;
  GPIO_InitStruct.Speed = GPIO_SPEED_FREQ_LOW;
  HAL_GPIO_Init(GPIOC, &GPIO_InitStruct);

  /*Configure GPIO pins : M1_STAT_34_Pin HORN_nCLIP_Pin */
  GPIO_InitStruct.Pin = M1_STAT_34_Pin|HORN_nCLIP_Pin;
  GPIO_InitStruct.Mode = GPIO_MODE_INPUT;
  GPIO_InitStruct.Pull = GPIO_NOPULL;
  HAL_GPIO_Init(GPIOC, &GPIO_InitStruct);

  /*Configure GPIO pins : M1_3_TRIG_Pin M1_2_TRIG_Pin M1_1_TRIG_Pin MOS_SPI_M0_ADC_nCS_Pin
                           M3_4_TRIG_Pin M3_3_TRIG_Pin M3_2_TRIG_Pin M3_1_TRIG_Pin */
  GPIO_InitStruct.Pin = M1_3_TRIG_Pin|M1_2_TRIG_Pin|M1_1_TRIG_Pin|MOS_SPI_M0_ADC_nCS_Pin
                          |M3_4_TRIG_Pin|M3_3_TRIG_Pin|M3_2_TRIG_Pin|M3_1_TRIG_Pin;
  GPIO_InitStruct.Mode = GPIO_MODE_OUTPUT_PP;
  GPIO_InitStruct.Pull = GPIO_NOPULL;
  GPIO_InitStruct.Speed = GPIO_SPEED_FREQ_LOW;
  HAL_GPIO_Init(GPIOA, &GPIO_InitStruct);

  /*Configure GPIO pins : M1_STAT_12_Pin M3_STAT_34_Pin M3_STAT_12_Pin */
  GPIO_InitStruct.Pin = M1_STAT_12_Pin|M3_STAT_34_Pin|M3_STAT_12_Pin;
  GPIO_InitStruct.Mode = GPIO_MODE_INPUT;
  GPIO_InitStruct.Pull = GPIO_NOPULL;
  HAL_GPIO_Init(GPIOA, &GPIO_InitStruct);

  /*Configure GPIO pins : M0_34_STAT_Pin HORN_nFLT_Pin */
  GPIO_InitStruct.Pin = M0_34_STAT_Pin|HORN_nFLT_Pin;
  GPIO_InitStruct.Mode = GPIO_MODE_INPUT;
  GPIO_InitStruct.Pull = GPIO_NOPULL;
  HAL_GPIO_Init(GPIOB, &GPIO_InitStruct);

  /*Configure GPIO pins : M0_2_TRIG_Pin M0_1_TRIG_Pin HORN_AMP_EN_Pin */
  GPIO_InitStruct.Pin = M0_2_TRIG_Pin|M0_1_TRIG_Pin|HORN_AMP_EN_Pin;
  GPIO_InitStruct.Mode = GPIO_MODE_OUTPUT_PP;
  GPIO_InitStruct.Pull = GPIO_NOPULL;
  GPIO_InitStruct.Speed = GPIO_SPEED_FREQ_LOW;
  HAL_GPIO_Init(GPIOB, &GPIO_InitStruct);

  /*Configure GPIO pins : M0_STAT_12_Pin VCC_I_nFLT_Pin LED_A_SUP_nFLT_Pin LED_B_SUP_nFLT_Pin
                           LED_C_SUP_nFLT_Pin LED_D_SUP_nFLT_Pin BCM_SUP_nFLT_Pin HORN_SUP_nFLT_Pin */
  GPIO_InitStruct.Pin = M0_STAT_12_Pin|VCC_I_nFLT_Pin|LED_A_SUP_nFLT_Pin|LED_B_SUP_nFLT_Pin
                          |LED_C_SUP_nFLT_Pin|LED_D_SUP_nFLT_Pin|BCM_SUP_nFLT_Pin|HORN_SUP_nFLT_Pin;
  GPIO_InitStruct.Mode = GPIO_MODE_INPUT;
  GPIO_InitStruct.Pull = GPIO_NOPULL;
  HAL_GPIO_Init(GPIOE, &GPIO_InitStruct);

  /*Configure GPIO pin : HORN_I_nFLT_Pin */
  GPIO_InitStruct.Pin = HORN_I_nFLT_Pin;
  GPIO_InitStruct.Mode = GPIO_MODE_INPUT;
  GPIO_InitStruct.Pull = GPIO_PULLUP;
  HAL_GPIO_Init(HORN_I_nFLT_GPIO_Port, &GPIO_InitStruct);

  /*Configure GPIO pins : MOS_SPI_ADC_0_nCS_Pin MOS_SPI_M3_ADC_nCS_Pin MOS_SPI_ADC_2_nCS_Pin MOS_SPI_ADC_1_nCS_Pin
                           IO_CHK_0_nRST_Pin M2_4_TRIG_Pin M2_3_TRIG_Pin M2_2_TRIG_Pin
                           M2_1_TRIG_Pin IO_CHK_1_nRST_Pin */
  GPIO_InitStruct.Pin = MOS_SPI_ADC_0_nCS_Pin|MOS_SPI_M3_ADC_nCS_Pin|MOS_SPI_ADC_2_nCS_Pin|MOS_SPI_ADC_1_nCS_Pin
                          |IO_CHK_0_nRST_Pin|M2_4_TRIG_Pin|M2_3_TRIG_Pin|M2_2_TRIG_Pin
                          |M2_1_TRIG_Pin|IO_CHK_1_nRST_Pin;
  GPIO_InitStruct.Mode = GPIO_MODE_OUTPUT_PP;
  GPIO_InitStruct.Pull = GPIO_NOPULL;
  GPIO_InitStruct.Speed = GPIO_SPEED_FREQ_LOW;
  HAL_GPIO_Init(GPIOD, &GPIO_InitStruct);

  /*Configure GPIO pins : IO_CHK_0_INTB_Pin IO_CHK_0_INTA_Pin */
  GPIO_InitStruct.Pin = IO_CHK_0_INTB_Pin|IO_CHK_0_INTA_Pin;
  GPIO_InitStruct.Mode = GPIO_MODE_IT_RISING;
  GPIO_InitStruct.Pull = GPIO_NOPULL;
  HAL_GPIO_Init(GPIOD, &GPIO_InitStruct);

  /*Configure GPIO pins : M2_STAT_34_Pin M2_STAT_12_Pin */
  GPIO_InitStruct.Pin = M2_STAT_34_Pin|M2_STAT_12_Pin;
  GPIO_InitStruct.Mode = GPIO_MODE_INPUT;
  GPIO_InitStruct.Pull = GPIO_NOPULL;
  HAL_GPIO_Init(GPIOD, &GPIO_InitStruct);

  /*Configure GPIO pins : IO_CHK_1_INTB_Pin IO_CHK_1_INTA_Pin */
  GPIO_InitStruct.Pin = IO_CHK_1_INTB_Pin|IO_CHK_1_INTA_Pin;
  GPIO_InitStruct.Mode = GPIO_MODE_IT_RISING;
  GPIO_InitStruct.Pull = GPIO_NOPULL;
  HAL_GPIO_Init(GPIOB, &GPIO_InitStruct);

  /*AnalogSwitch Config */
  HAL_SYSCFG_AnalogSwitchConfig(SYSCFG_SWITCH_PC3, SYSCFG_SWITCH_PC3_CLOSE);

  /*AnalogSwitch Config */
  HAL_SYSCFG_AnalogSwitchConfig(SYSCFG_SWITCH_PA0, SYSCFG_SWITCH_PA0_CLOSE);

  /*AnalogSwitch Config */
  HAL_SYSCFG_AnalogSwitchConfig(SYSCFG_SWITCH_PA1, SYSCFG_SWITCH_PA1_CLOSE);

}

 /* MPU Configuration */

void MPU_Config(void)
{
  MPU_Region_InitTypeDef MPU_InitStruct = {0};

  /* Disables the MPU */
  HAL_MPU_Disable();

  /** Initializes and configures the Region and the memory to be protected
  */
  MPU_InitStruct.Enable = MPU_REGION_ENABLE;
  MPU_InitStruct.Number = MPU_REGION_NUMBER0;
  MPU_InitStruct.BaseAddress = 0x0;
  MPU_InitStruct.Size = MPU_REGION_SIZE_4GB;
  MPU_InitStruct.SubRegionDisable = 0x87;
  MPU_InitStruct.TypeExtField = MPU_TEX_LEVEL0;
  MPU_InitStruct.AccessPermission = MPU_REGION_NO_ACCESS;
  MPU_InitStruct.DisableExec = MPU_INSTRUCTION_ACCESS_DISABLE;
  MPU_InitStruct.IsShareable = MPU_ACCESS_SHAREABLE;
  MPU_InitStruct.IsCacheable = MPU_ACCESS_NOT_CACHEABLE;
  MPU_InitStruct.IsBufferable = MPU_ACCESS_NOT_BUFFERABLE;

  HAL_MPU_ConfigRegion(&MPU_InitStruct);
  /* Enables the MPU */
  HAL_MPU_Enable(MPU_PRIVILEGED_DEFAULT);

}

void Error_Handler(void)
{
  __disable_irq();
  while (1)
  {
  }
}
